# STM32L0x0 register map
File version: 1.1
CPU: CM0+ r0p0, little endian, MPU, no FPU, 4 interrupt priority bits
Registers are 32-bit, read-write, reset 0x0 unless marked. A register's access mark holds for its fields unless they carry their own. Offsets are from the block's base; lines under a group give offsets from that group; [hi:lo] are bit positions; {n}, {i} and the like mark numbered series; 'fields as' and 'values as' point back to an identical list; <NAME> marks a mode.

## Memory map
0x40000000 TIM2 size 0x400 — General-purpose-timers
0x40002800 RTC size 0x400 — Real-time clock
0x40002C00 WWDG size 0x400 — System window watchdog
0x40003000 IWDG size 0x400 — Independent watchdog
0x40004400 USART2 size 0x400 — Universal synchronous asynchronous receiver transmitter
0x40004800 LPUART1 size 0x400 — Lower power Universal asynchronous receiver transmitter
0x40005400 I2C1 size 0x400 — Inter-integrated circuit
0x40007000 PWR size 0x400 — Power control
0x40007C00 LPTIM size 0x400 — Low power timer
0x40010000 SYSCFG size 0x400 — System configuration controller register
0x40010400 EXTI size 0x400 — External interrupt/event controller
0x40010800 TIM21 size 0x400 — General-purpose-timers
0x40011400 TIM22 size 0x400 — General-purpose-timers
0x40011C00 Firewall size 0x400
0x40012400 ADC size 0x400 — Analog-to-digital converter
0x40013000 SPI1 size 0x400 — Serial peripheral interface
0x40015800 DBG size 0x400 — Debug support
0x40020000 DMA1 size 0x400 — Direct memory access controller
0x40021000 RCC size 0x400 — Reset and clock control
0x40022000 Flash size 0x400
0x40023000 CRC size 0x400 — Cyclic redundancy check calculation unit
0x50000000 GPIOA size 0x400 — General-purpose I/Os
0x50000400 GPIOB size 0x400 — General-purpose I/Os
0x50000800 GPIOC size 0x400
0x50000C00 GPIOD size 0x400
0x50001000 GPIOE size 0x400
0x50001C00 GPIOH size 0x400
0xE000E010 STK size 0x11 — SysTick timer
0xE000E100 NVIC size 0x33D — Nested Vectored Interrupt Controller
0xE000ED00 SCB size 0x41 — System control block
0xE000ED90 MPU size 0x15 — Memory protection unit

## Interrupts
0 WWDG (Firewall) — Window Watchdog interrupt
2 RTC — RTC global interrupt
3 FLASH (EXTI) — Flash global interrupt
4 RCC (SYSCFG) — RCC global interrupt
5 EXTI0_1 (ADC) — EXTI Line[1:0] interrupts
6 EXTI2_3 (ADC) — EXTI Line[3:2] interrupts
7 EXTI4_15 (ADC) — EXTI Line15 and EXTI4 interrupts
9 DMA1_Channel1 (DMA1) — DMA1 Channel1 global interrupt
10 DMA1_Channel2_3 (DMA1) — DMA1 Channel2 and 3 interrupts
11 DMA1_Channel4_7 (DMA1) — DMA1 Channel4 to 7 interrupts
12 ADC (DBG)
13 LPTIM1 (LPTIM) — LPTIMER1 interrupt through EXTI29
15 TIM2 (TIM21) — TIM2 global interrupt
20 TIM21 (TIM22) — TIMER21 global interrupt
22 TIM22 (LPUART1) — TIMER22 global interrupt
23 I2C1 (PWR) — I2C1 global interrupt
25 SPI1 (I2C1) — SPI1_global_interrupt
28 USART2 (IWDG) — USART2 global interrupt
29 LPUART1 (NVIC) — LPUART1 global interrupt through

## DMA1 — Direct memory access controller
Base 0x40020000
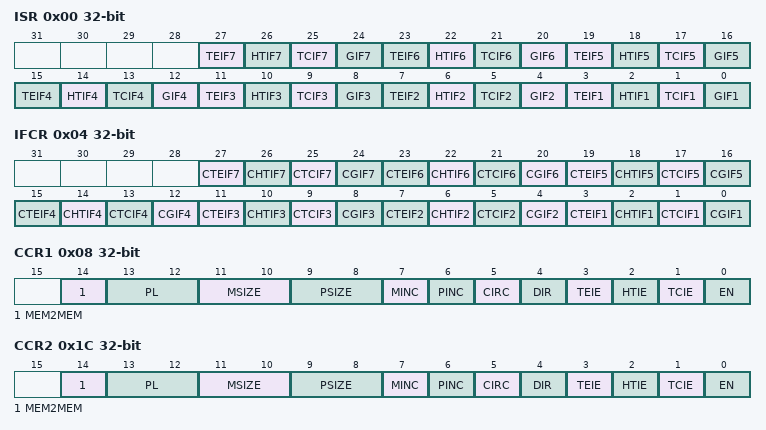
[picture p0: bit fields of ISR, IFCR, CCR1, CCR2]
0x00 ISR ro — interrupt status register
  [4n-1] TEIF{n} (n=1..7) — Channel x transfer error flag (x = 1 ..7)
  [4n-2] HTIF{n} (n=1..7) — Channel x half transfer flag (x = 1 ..7)
  [4n-3] TCIF{n} (n=1..7) — Channel x transfer complete flag (x = 1 ..7)
  [4n-4] GIF{n} (n=1..7) — Channel x global interrupt flag (x = 1 ..7)
0x04 IFCR wo — interrupt flag clear register
  [4n-1] CTEIF{n} (n=1..7) — Channel x transfer error clear (x = 1 ..7)
  [4n-2] CHTIF{n} (n=1..7) — Channel x half transfer clear (x = 1 ..7)
  [4n-3] CTCIF{n} (n=1..7) — Channel x transfer complete clear (x = 1 ..7)
  [4n-4] CGIF{n} (n=1..7) — Channel x global interrupt clear (x = 1 ..7)
0x08 CCR1 — channel x configuration register
  [14] MEM2MEM — Memory to memory mode
  [13:12] PL — Channel priority level
  [11:10] MSIZE — Memory size
  [9:8] PSIZE — Peripheral size
  [7] MINC — Memory increment mode
  [6] PINC — Peripheral increment mode
  [5] CIRC — Circular mode
  [4] DIR — Data transfer direction
  [3] TEIE — Transfer error interrupt enable
  [2] HTIE — Half transfer interrupt enable
  [1] TCIE — Transfer complete interrupt enable
  [0] EN — Channel enable
0x0C CNDTR1 — channel x number of data register
  [15:0] NDT — Number of data to transfer
0x10 CPAR1 — channel x peripheral address register
  [31:0] PA — Peripheral address
{0x0+0x14*i} CMAR{i} (i=1..7) — channel x memory address register
  [31:0] MA — Memory address
0x1C CCR2 — channel x configuration register
  fields as CCR1
0x20 CNDTR2 — channel x number of data register
  [15:0] NDT — Number of data to transfer
0x24 CPAR2 — channel x peripheral address register
  [31:0] PA — Peripheral address
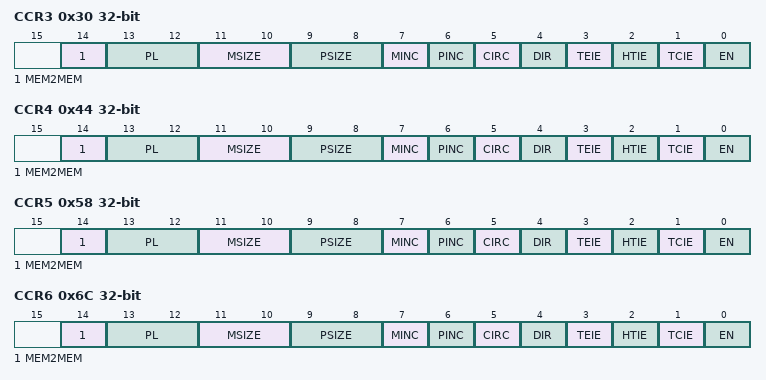
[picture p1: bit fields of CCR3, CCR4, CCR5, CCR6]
0x30 CCR3 — channel x configuration register
  fields as CCR1
0x34 CNDTR3 — channel x number of data register
  [15:0] NDT — Number of data to transfer
0x38 CPAR3 — channel x peripheral address register
  [31:0] PA — Peripheral address
0x44 CCR4 — channel x configuration register
  fields as CCR1
0x48 CNDTR4 — channel x number of data register
  [15:0] NDT — Number of data to transfer
0x4C CPAR4 — channel x peripheral address register
  [31:0] PA — Peripheral address
0x58 CCR5 — channel x configuration register
  fields as CCR1
0x5C CNDTR5 — channel x number of data register
  [15:0] NDT — Number of data to transfer
0x60 CPAR5 — channel x peripheral address register
  [31:0] PA — Peripheral address
0x6C CCR6 — channel x configuration register
  fields as CCR1
0x70 CNDTR6 — channel x number of data register
  [15:0] NDT — Number of data to transfer
0x74 CPAR6 — channel x peripheral address register
  [31:0] PA — Peripheral address
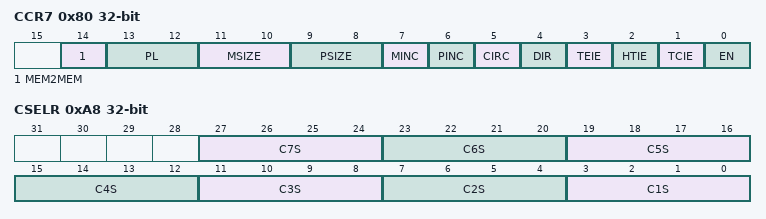
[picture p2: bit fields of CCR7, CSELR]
0x80 CCR7 — channel x configuration register
  fields as CCR1
0x84 CNDTR7 — channel x number of data register
  [15:0] NDT — Number of data to transfer
0x88 CPAR7 — channel x peripheral address register
  [31:0] PA — Peripheral address
0xA8 CSELR — channel selection register
  [4n-1:4n-4] C{n}S (n=1..7) — DMA channel {n} selection
